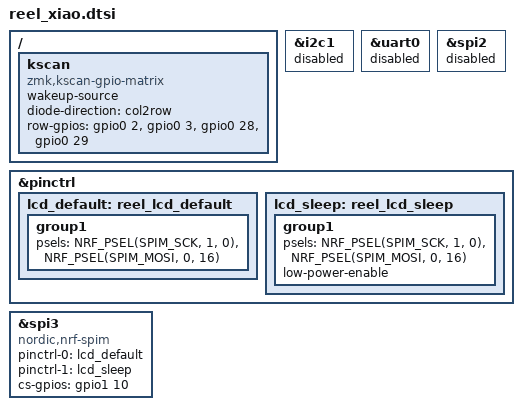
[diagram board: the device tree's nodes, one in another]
#include "reel.dtsi"

&i2c1 { status = "disabled"; };
&uart0 { status = "disabled"; };
&spi2 { status = "disabled"; };

&pinctrl {
    lcd_default: reel_lcd_default {
        group1 { psels = <NRF_PSEL(SPIM_SCK, 1, 0)>, <NRF_PSEL(SPIM_MOSI, 0, 16)>; };
    };
    lcd_sleep: reel_lcd_sleep {
        group1 {
            psels = <NRF_PSEL(SPIM_SCK, 1, 0)>, <NRF_PSEL(SPIM_MOSI, 0, 16)>;
            low-power-enable;
        };
    };
};

nice_view_spi: &spi3 {
    compatible = "nordic,nrf-spim";
    pinctrl-0 = <&lcd_default>;
    pinctrl-1 = <&lcd_sleep>;
    pinctrl-names = "default", "sleep";
    cs-gpios = <&gpio1 10 GPIO_ACTIVE_HIGH>;
};

/ {
    kscan: kscan {
        compatible = "zmk,kscan-gpio-matrix";
        wakeup-source;
        diode-direction = "col2row";
        row-gpios = <&gpio0 2 (GPIO_ACTIVE_HIGH | GPIO_PULL_DOWN)>,
                    <&gpio0 3 (GPIO_ACTIVE_HIGH | GPIO_PULL_DOWN)>,
                    <&gpio0 28 (GPIO_ACTIVE_HIGH | GPIO_PULL_DOWN)>,
                    <&gpio0 29 (GPIO_ACTIVE_HIGH | GPIO_PULL_DOWN)>;
    };
};
